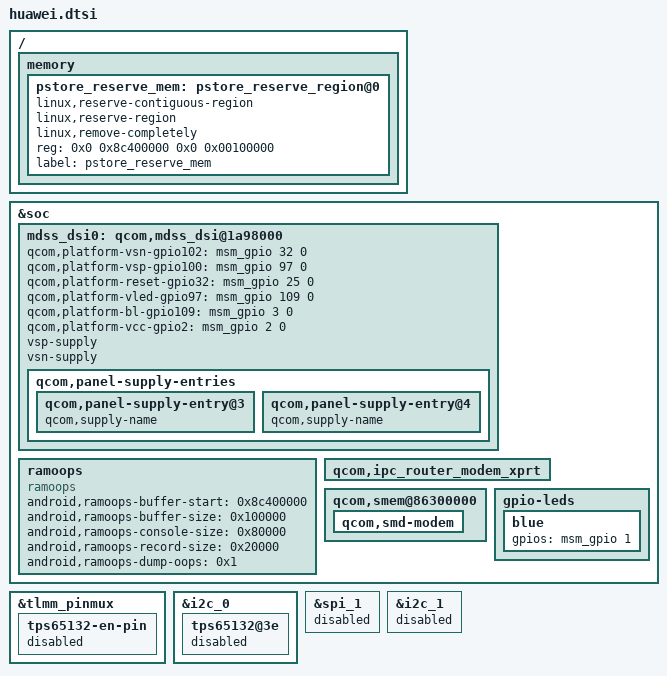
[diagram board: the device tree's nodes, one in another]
/*                                      Regulations
1.The "DTSxxx" just be allowed to  add at the begin and the tail.
2.The dtsi files which belong to a group need to be put together,and will be separated by remarks.
3.When we add one new boardid,it would be inherted from the similar one
 and modify the product name in the files of huawei-fac.dtsi huawei-wifi.dtsi huawei-audio.dtsi,
 and the other groups need to do some modify with DTSxxx.
*/
/*belong to the component group, according to the order of i2c lcd tp camera sensors compass tricolors vibrator begin*/

#include "huawei-lcd.dtsi"
#include "huawei-tp.dtsi"
#include "huawei-camera.dtsi"
#include "huawei-sensors.dtsi"
#include "huawei-vibrator.dtsi"
#include "huawei-audio.dtsi"
#include "huawei-battery.dtsi"
#include "huawei-fingerprint.dtsi"
#include "huawei-sdcard.dtsi"
#include "huawei-usb.dtsi"
#include "huawei-gpio.dtsi"

/ {
	memory {
		pstore_reserve_mem: pstore_reserve_region@0 {
			linux,reserve-contiguous-region;
			linux,reserve-region;
			linux,remove-completely;
			reg = <0x0 0x8c400000 0x0 0x00100000>;
			label = "pstore_reserve_mem";
		};
	};
};

/*Rename GPIO*/
&soc {
	mdss_dsi0: qcom,mdss_dsi@1a98000 {
		/delete-property/ qcom,gpio-cs0;
		/delete-property/ qcom,gpio-clk;
		/delete-property/ ti,en-gpio;
		qcom,platform-vsn-gpio102 = <&msm_gpio 32 0>;
		qcom,platform-vsp-gpio100 = <&msm_gpio 97 0>;
		qcom,platform-reset-gpio32 = <&msm_gpio 25 0>;
		qcom,platform-vled-gpio97 = <&msm_gpio 109 0>;
		qcom,platform-bl-gpio109 = <&msm_gpio 3 0>;
		qcom,platform-vcc-gpio2 = <&msm_gpio 2 0>;
	};

	ramoops {
		compatible = "ramoops";
		status = "ok";

		/* This is tacked at the end of pheripheral_region@0 */
		android,ramoops-buffer-start = <0x8c400000>;
		android,ramoops-buffer-size = <0x100000>;
		android,ramoops-console-size = <0x80000>;
		android,ramoops-record-size = <0x20000>;
		android,ramoops-dump-oops = <0x1>;
	};

	qcom,ipc_router_modem_xprt {
		/delete-property/ qcom,disable-pil-loading;
	};

	qcom,smem@86300000 {
		qcom,smd-modem {
			/delete-property/ qcom,not-loadable;
		};

	/delete-node/ cdc-ext-spk-pa;
	/delete-node/ regulator_spk;
	/delete-node/ qcom,leds@a100;
    /* Delete for now display nodes */
	/delete-node/ ddic_rst_active;
	/delete-node/ ddic_rst_suspend;
	/delete-node/ mod_en_active;
	/delete-node/ mod_en_suspend;
	};

	/* Since blue led gpio is specified to GPIO 10 in msm8939-qrd-skuk.dtsi and PELE owns no blue led, so re-assign it to a unused GPIO here. */
	gpio-leds {
		blue {
			gpios = <&msm_gpio 1 0>;
		};
	};
};

&tlmm_pinmux {
	tps65132-en-pin {
		status = "disabled";
	};
};

&i2c_0 {
	tps65132@3e {
		status = "disabled";
	};
};

&mdss_dsi0 {
	vsp-supply;
	vsn-supply;
	qcom,panel-supply-entries {
		qcom,panel-supply-entry@3 {
			qcom,supply-name;
		};
		qcom,panel-supply-entry@4 {
			qcom,supply-name;
		};
	};
};

/* Disable BLSP1_SPI(GPIO 1,2,3,4) since these gpios are used for other purpose */
&spi_1 {
	status = "disabled";
};

/* Disable BLSP1_I2C (GPIO 2,3) since these gpios are used for other purpose */
&i2c_1 {
	status = "disabled";
};
